# apollo510 register map
Vendor: Ambiq Micro; Series: Apollo; File version: 1.0
CPU: CM55 r1p1, little endian, MPU, FPU, double-precision FPU, DSP, I-cache, D-cache, VTOR, ITCM, DTCM, 4 interrupt priority bits, 0 interrupts, 8 SAU regions
Registers are 32-bit, read-write, reset 0x0 unless marked. A register's access mark holds for its fields unless they carry their own. Offsets are from the block's base; [hi:lo] are bit positions; {n}, {i} and the like mark numbered series; 'fields as' and 'values as' point back to an identical list.

## MCUCTRL (part 1 of 2) — MCU Miscellaneous Control Logic
Base 0x40020000
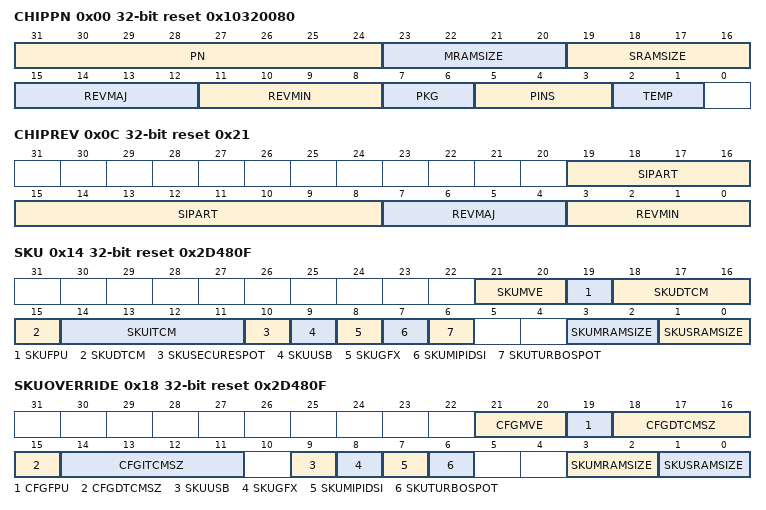
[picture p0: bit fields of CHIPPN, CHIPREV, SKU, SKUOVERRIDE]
0x00 CHIPPN reset 0x10320080 — Chip Information
  [31:24] PN — Apollo family device type.
    16=APOLLO5 (Apollo510 part number is 0x10xxxxxx.)
  [23:20] MRAMSIZE — MRAM size. Please use the SKU register for determining memory sizing.
    {v}={v+1}MB (MRAM size is {v+1}MB.) (v=0..3)
  [19:16] SRAMSIZE — SRAM size. Please use the SKU register for determining memory sizing.
    3=ITCM256K_DTCM512K_SSRAM3M (ITCM=256KB, DTCM=512KB, SSRAM=3MB); 2=ITCM256K_DTCM512K_SSRAM2M (ITCM=256KB, DTCM=512KB, SSRAM=2MB); 1=ITCM128K_DTCM256K_SSRAM2M (ITCM=128KB, DTCM=256KB, SSRAM=2MB); 0=ITCM128K_DTCM256K_SSRAM1M (ITCM=128KB, DTCM=256KB, SSRAM=1MB)
  [15:12] REVMAJ — Major revision. Please use the CHIPREV register for device identification.
  [11:8] REVMIN — Minor revision. Please use the CHIPREV register for device identification.
  [7:6] PKG — Package type.
    0=SIP (SIP package.); 1=SIP2 (SIP2 package.); 2=BGA (BGA package.); 3=CSP (CSP package.)
  [5:3] PINS — Number of pins for a given package.
    2=SIP153 (Apollo510 SIP pins = 153 (97 GPIO).); 4=BGA225 (Apollo510 BGA pins = 225 (183 GPIO).); 5=CSP182 (Apollo510 BGA pins = 182 (144 GPIO).)
  [2:1] TEMP — Temperature.
0x04 CHIPID0 — Unique Chip ID 0
  [31:0] CHIPID0 — Unique chip ID 0. For APOLLO CHIPID0 value is 0x0
0x08 CHIPID1 — Unique Chip ID 1
  [31:0] CHIPID1 — Unique chip ID 1. For APOLLO CHIPID1 value is 0x0
0x0C CHIPREV reset 0x21 — Chip Revision
  [19:8] SIPART — Silicon Part ID
  [7:4] REVMAJ — Major Revision ID.
    3=C (Apollo510 revision C); 2=B (Apollo510 revision B); 1=A (Apollo510 revision A)
  [3:0] REVMIN — Minor Revision ID.
    3=REV2 (Apollo510 minor rev 2.); 2=REV1 (Apollo510 minor rev 1.); 1=REV0 (Apollo510 minor rev 0. Minor revision value, succeeding minor revisions will increment from this value.)
0x10 VENDORID — Unique Vendor ID
  [31:0] VENDORID
    0x414D4251=AMBIQ (Ambiq Vendor ID 'AMBQ'); 0=DEFAULT (Default Vendor ID)
0x14 SKU reset 0x2D480F — Unique Chip SKU
  [21:20] SKUMVE — MVE feature 0x0: no MVE 0x1: Integer MVE only 0x2: Integer and Floating Point MVE supported (note that with this setting, FPU must be enabled)
  [19] SKUFPU — FPU feature 0x0: no FPU 0x1: Has FPU
  [18:15] SKUDTCM — DTCM size feature 0x8: 128KB 0x9: 256KB 0xA: 512KB
  [14:11] SKUITCM — ITCM size feature 0x6: 32KB 0x8: 128KB 0x9: 256KB
  [10] SKUSECURESPOT — Secure boot feature
  [9] SKUUSB — USB available
  [8] SKUGFX — GFX available
  [7] SKUMIPIDSI — MIPI DSI available
  [6] SKUTURBOSPOT — High performance mode for MCU and DSPs.
  [3:2] SKUMRAMSIZE — MRAM size SKU. All of 4MB Available by default.
    {v}={v+1}MB (Total available MRAM size is {v+1}MB.) (v=0..3)
  [1:0] SKUSRAMSIZE — SRAM SKU dictates the available memory for MCU. All of the MCU TCM (384KB) and System SRAM (2MB) available by default.
    0=1MB (Total available System SRAM size is 1MB (SSRAM0 only).); 1=2MB (Total available System SRAM size is 2MB (SSRAM0 and SSRAM1).); 3=3MB (Total available System SRAM size is 3MB (SSRAM0, SSRAM1, and SSRAM2).)
0x18 SKUOVERRIDE reset 0x2D480F — Override register for Chip SKU
  [21:20] CFGMVE — MVE feature
  [19] CFGFPU — FPU feature
  [18:15] CFGDTCMSZ — DTCM size feature (only 3 DTCM configurations are allowed: 0x8 - 128K, 0x9 - 256K, 0xA - 512K)
  [14:11] CFGITCMSZ — ITCM size feature (only 3 ITCM configurations are allowed: 0x6 - 32K, 0x8 - 128K, 0x9 - 256K)
  [9] SKUUSB — Override for usb sku
  [8] SKUGFX — Override for gfx sku
  [7] SKUMIPIDSI — Override for mipi dsi sku
  [6] SKUTURBOSPOT — Override for turbo spot sku
  [3:2] SKUMRAMSIZE — Override for mram size sku
  [1:0] SKUSRAMSIZE — Override for sram size sku
0x20 DEBUGGER — Debugger Control
  [31:0] LOCKOUT — Lockout of debugger (SWD).
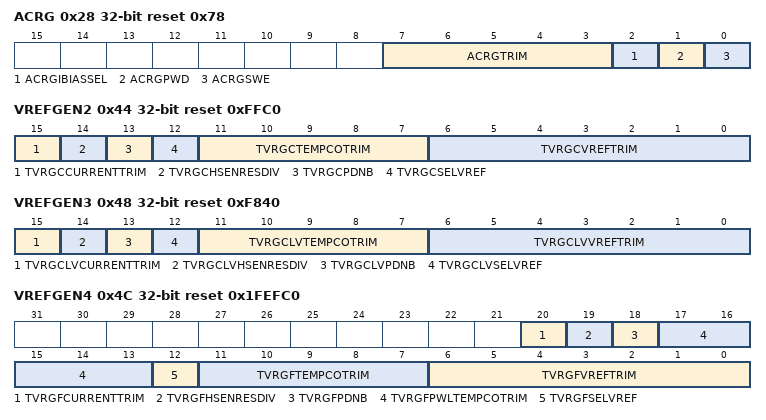
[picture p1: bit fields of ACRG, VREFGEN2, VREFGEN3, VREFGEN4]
0x28 ACRG reset 0x78 — Active Current Reference Generator Control
  [7:3] ACRGTRIM — ACRG Trim value
  [2] ACRGIBIASSEL — Set the ACRG ibias. Note: the SWE mux select in PWRSEQ2SWE must be set for this to take effect. The inversion of this register is driven to analog.
    0=BGSEL (Selects the bandgap); 1=CCRGSEL (Selects the CCRG)
  [1] ACRGPWD — Power down the ACRG.
    1=ACRG_PWR_DN (Powers down the ACRG trim.); 0=ACRG_PWR_UP (Power up the ACRG trim.)
  [0] ACRGSWE — Software enablement for ACRG register. A value of 1 will allow writes to the register
0x44 VREFGEN2 reset 0xFFC0 — Voltage Reference Generator 2 Control
  [15] TVRGCCURRENTTRIM — TVRGC Current trim init value
  [14] TVRGCHSENRESDIV — TVRGC hsenable resdiv init value
  [13] TVRGCPDNB — TVRGC pdnb init value
  [12] TVRGCSELVREF — TVRGC sel vref init value
  [11:7] TVRGCTEMPCOTRIM — TVRGC tempcompensation trim init value
  [6:0] TVRGCVREFTRIM — Calibrated Voltage Reference Generator tc trim (bottom transistor)
0x48 VREFGEN3 reset 0xF840 — Voltage Reference Generator 3 Control
  [15] TVRGCLVCURRENTTRIM — TVRGCLV Current trim init value
  [14] TVRGCLVHSENRESDIV — TVRGCLV hsenable resdiv init value
  [13] TVRGCLVPDNB — TVRGCLV pdnb init value
  [12] TVRGCLVSELVREF — TVRGCLV sel vref init value
  [11:7] TVRGCLVTEMPCOTRIM — TVRGCLV tempco trim init value
  [6:0] TVRGCLVVREFTRIM — TVRGCLV Voltage Reference Generator trim (bottom transistor)
0x4C VREFGEN4 reset 0x1FEFC0 — Voltage Reference Generator 4 Control
  [20] TVRGFCURRENTTRIM — TVRGF Current trim init value
  [19] TVRGFHSENRESDIV — TVRGF hsenable resdiv init value
  [18] TVRGFPDNB — TVRGF pdnb init value
  [17:13] TVRGFPWLTEMPCOTRIM — Calibrated Voltage Reference Generator pwl tc trim (bottom transistor)
  [12] TVRGFSELVREF — TVRGF sel vref init value
  [11:7] TVRGFTEMPCOTRIM — TVRGF tempo trim init value
  [6:0] TVRGFVREFTRIM — TVRGF Voltage Reference Generator trim (bottom transistor)
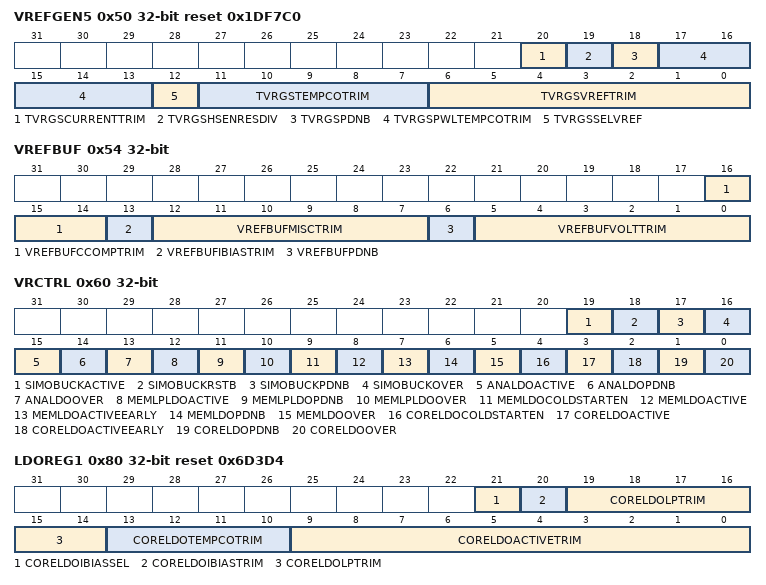
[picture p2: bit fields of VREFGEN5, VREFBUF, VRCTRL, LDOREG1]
0x50 VREFGEN5 reset 0x1DF7C0 — Voltage Reference Generator 5 Control
  [20] TVRGSCURRENTTRIM — TVRGS Current trim init value
  [19] TVRGSHSENRESDIV — TVRGS hsenable resdiv init value
  [18] TVRGSPDNB — TVRGS pdnb init value
  [17:13] TVRGSPWLTEMPCOTRIM — Calibrated Voltage Reference Generator pwl tc trim (bottom transistor)
  [12] TVRGSSELVREF — TVRGS sel vref init value
  [11:7] TVRGSTEMPCOTRIM — TVRGS tempo trim init value
  [6:0] TVRGSVREFTRIM — TVRGS Voltage Reference Generator trim (bottom transistor)
0x54 VREFBUF — Voltage Reference BUF Control
  [16:14] VREFBUFCCOMPTRIM — VREFBUF ccomp trim init value
  [13] VREFBUFIBIASTRIM — VREFBUFIBIAS trim init value
  [12:7] VREFBUFMISCTRIM — VREFBUF MISC trim init value
  [6] VREFBUFPDNB — VREGBUF pdnb init value
  [5:0] VREFBUFVOLTTRIM — VREFBUF voltage trim init value
0x60 VRCTRL — Overrides for Voltage Regulators Controls
  [19] SIMOBUCKACTIVE — SIMO BUCK ACTIVE control. Override for PWRCTRL going to analog when SIMOBUCKOVER = 1
  [18] SIMOBUCKRSTB — SIMO BUCK RSTB control. Override for PWRCTRL going to analog when SIMOBUCKOVER = 1
  [17] SIMOBUCKPDNB — SIMO BUCK PDNB control. Override for PWRCTRL going to analog when SIMOBUCKOVER = 1
  [16] SIMOBUCKOVER — Override control for SIMO BUCK signals
  [15] ANALDOACTIVE — ANALDO LDO ACTIVE control. Override for PWRCTRL going to analog when ANALDOOVER = 1
  [14] ANALDOPDNB — ANALDO PDNB control. Override for PWRCTRL going to analog when ANALDOOVER = 1
  [13] ANALDOOVER — Override control for ANALDO signals
  [12] MEMLPLDOACTIVE — MEM LP LDO ACTVIVE control. Override for PWRCTRL going to analog when MEMLPLDOOVER = 1
  [11] MEMLPLDOPDNB — MEM LP LDO PDNB control. Override for PWRCTRL going to analog when MEMLPLDOOVER = 1
  [10] MEMLPLDOOVER — Override control for MEM LP LDO signals
  [9] MEMLDOCOLDSTARTEN — MEM LDO COLDSTART EN control. This is a shadow backed register and no need to set MEMLDOOVER.
  [8] MEMLDOACTIVE — MEM LDO ACTIVE control. Override for PWRCTRL going to analog when MEMLDOOVER = 1
  [7] MEMLDOACTIVEEARLY — MEM LDO EARLY ACTIVE control. Override for PWRCTRL going to analog when MEMLDOOVER = 1
  [6] MEMLDOPDNB — MEM LDO PDNB control. Override signal for PWRCTRL going to analog when MEMLDOOVER = 1
  [5] MEMLDOOVER — Override control for MEM LDO signals
  [4] CORELDOCOLDSTARTEN — CORE LDO COLDSTART EN control. This is a shadow backed register and no need to set CORELDOOVER.
  [3] CORELDOACTIVE — CORE LDO ACTIVE control. Override for PWRCTRL going to analog when CORELDOOVER = 1
  [2] CORELDOACTIVEEARLY — CORE LDO EARLY ACTIVE control. Override for PWRCTRL going to analog when CORELDOOVER = 1
  [1] CORELDOPDNB — CORE LDO PDNB control. Override for PWRCTRL going to analog when CORELDOOVER = 1
  [0] CORELDOOVER — Override control for CORE LDO signals
0x80 LDOREG1 reset 0x6D3D4 — CORELDO trims Reg
  [21] CORELDOIBIASSEL — Core LDO IBIAS sel. Note: the SWE mux select in PWRSEQ2SWE must be set for this to take effect.
  [20] CORELDOIBIASTRIM
  [19:14] CORELDOLPTRIM — CORE LDO Low Power Trim
  [13:10] CORELDOTEMPCOTRIM
  [9:0] CORELDOACTIVETRIM
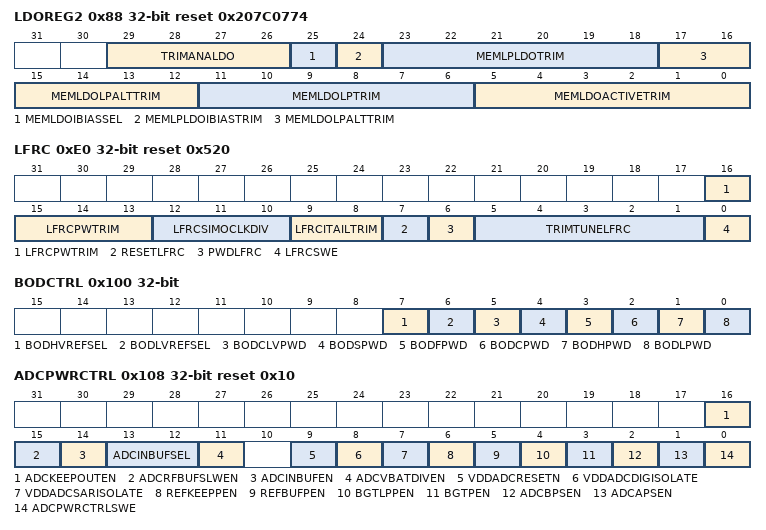
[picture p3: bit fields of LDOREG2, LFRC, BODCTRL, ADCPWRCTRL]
0x88 LDOREG2 reset 0x207C0774 — MEMLDO and MEMLPLDO Trims
  [29:26] TRIMANALDO — Analog LDO Trim.
  [25] MEMLDOIBIASSEL — Mem LDO IBIAS sel. Note: the SWE mux select in PWRSEQ2SWE must be set for this to take effect.
  [24] MEMLPLDOIBIASTRIM
  [23:18] MEMLPLDOTRIM
  [17:12] MEMLDOLPALTTRIM — MEM LDO TRIM LP ALT SET
  [11:6] MEMLDOLPTRIM
  [5:0] MEMLDOACTIVETRIM
0xE0 LFRC reset 0x520 — LFRC Control
  [16:13] LFRCPWTRIM — LFRC PW trim init value
  [12:10] LFRCSIMOCLKDIV — SIMOBUCK LP mode clock divider
    0=DIV1 (Divide by 1); 1=DIV2 (Divide by 2); 2=DIV4 (Divide by 4); 3=DIV8 (Divide by 8); 5=DIV32 (Inversion of DIV32)
  [9:8] LFRCITAILTRIM
  [7] RESETLFRC — LFRC Reset.
    0=EN (Enable LFRC.); 1=RESET (Reset LFRC.)
  [6] PWDLFRC — Power Down LFRC.
    0=PWRUP (Power up LFRC.); 1=PWRDN (Power down LFRC.)
  [5:1] TRIMTUNELFRC — LFRC Frequency Tune trim bits
  [0] LFRCSWE — LFRC Software Override Enable.
    0=OVERRIDE_DIS (LFRC Software Override Disable.); 1=OVERRIDE_EN (LFRC Software Override Enable.)
0x100 BODCTRL — BOD control
  [7] BODHVREFSEL — BODH External Reference Select. Note: the SWE mux select in PWRSEQ2SWE must be set for this to take effect.
  [6] BODLVREFSEL — BODL External Reference Select. Note: the SWE mux select in PWRSEQ2SWE must be set for this to take effect.
  [5] BODCLVPWD — BODC_LV Power Down.
  [4] BODSPWD — BODS Power Down.
  [3] BODFPWD — BODF Power Down.
  [2] BODCPWD — BODC Power Down.
  [1] BODHPWD — BODH Power Down.
  [0] BODLPWD — BODL Power Down.
0x108 ADCPWRCTRL reset 0x10 — ADC Power Control
  [16] ADCKEEPOUTEN — ADC reference keeper out en
  [15] ADCRFBUFSLWEN — ADC reference buffer slew enable
  [14] ADCINBUFEN — ADC Input Buffer Power Enable ( if the ADCPWRCTRLSWE bit is set )
  [13:12] ADCINBUFSEL — ADC input buffer mux select
  [11] ADCVBATDIVEN — ADC VBAT DIV Power Enable ( if the ADCPWRCTRLSWE bit is set )
  [9] VDDADCRESETN — RESETN signal for Power Switched SAR and Digital Controller (when global power switch is off and if the ADCPWRCTRLSWE bit is set)
    0=ASSERT (Resetn is asserted); 1=DEASSERT (Resetn is de-asserted)
  [8] VDDADCDIGISOLATE — ISOLATE signal for ADC Digital Contoller ( when ADCAPSEN is switched off and if the ADCPWRCTRLSWE bit is set)
    0=DIS (No Isolation); 1=EN (Isolate)
  [7] VDDADCSARISOLATE — ISOLATE signal for Power Switched SAR ( when ADCBPSEN is switched off )
    0=DIS (No Isolation); 1=EN (Isolate)
  [6] REFKEEPPEN — Reference Buffer Keeper Power Switch Enable
    0=DIS (Reference Buffer Keeper Power Switch disable.); 1=EN (Reference Buffer Keeper Power Switch enable.)
  [5] REFBUFPEN — Reference Buffer Power Switch Enable
    0=DIS (Reference Buffer Power Switch disable.); 1=EN (Reference Buffer Power Switch enable.)
  [4] BGTLPPEN — Bandgap and Temperature Sensor Power Switch Enable
    0=DIS (Bandgap and temperature sensor disable.); 1=EN (Bandgap and temperature sensor enable.)
  [3] BGTPEN — Bandgap and Temperature Sensor Power Switch Enable
    values as BGTLPPEN
  [2] ADCBPSEN — Enable the Analog, IO and SAR Digital logic Power Switch on when set to 1 if the ADCPWRCTRLSWE bit is set.
    0=DIS (ADC power switch software power disable.); 1=EN (ADC power switch software power enable.)
  [1] ADCAPSEN — Enable the Global ADC Power Switch on when set to 1 if the ADCPWRCTRLSWE bit is set.
    values as ADCBPSEN
  [0] ADCPWRCTRLSWE — ADC Power Control Software Override Enable
    0=OVERRIDE_DIS (ADC temperature sensor and bandgap Software Override Disable.); 1=OVERRIDE_EN (ADC temperature sensor and bandgap Software Override Enable.)
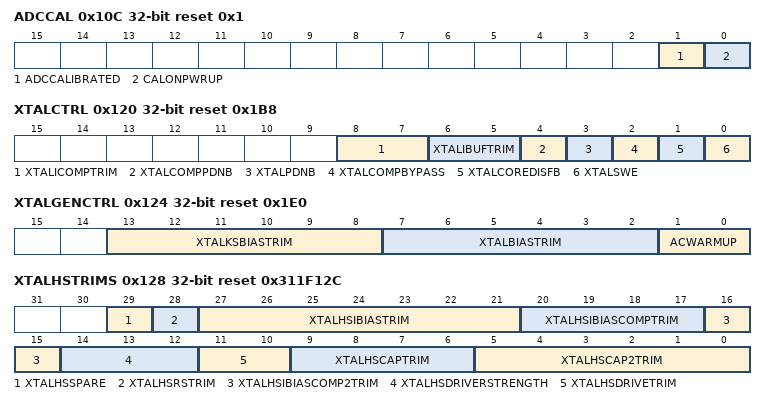
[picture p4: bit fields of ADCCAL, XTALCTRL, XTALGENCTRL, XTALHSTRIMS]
0x10C ADCCAL reset 0x1 — ADC Calibration Control
  [1] ADCCALIBRATED — Status for ADC Calibration
    0=FALSE (ADC is not calibrated); 1=TRUE (ADC is calibrated)
  [0] CALONPWRUP — Run ADC Calibration on initial power up sequence
    0=DIS (Disable automatic calibration on initial power up); 1=EN (Enable automatic calibration on initial power up)
0x110 ADCBATTLOAD — ADC Battery Load Enable
  [0] BATTLOAD — Enable the ADC battery load resistor
    0=DIS (Battery load is disconnected); 1=EN (Battery load is enabled)
0x120 XTALCTRL reset 0x1B8 — XTAL Oscillator Control
  [8:7] XTALICOMPTRIM
  [6:5] XTALIBUFTRIM — XTAL IBUFF trim
  [4] XTALCOMPPDNB — XTAL Oscillator Power Down Comparator.
    1=PWRUPCOMP (Power up XTAL oscillator comparator.); 0=PWRDNCOMP (Power down XTAL oscillator comparator.)
  [3] XTALPDNB — XTAL Oscillator Power Down Core.
    1=PWRUPCORE (Power up XTAL oscillator core.); 0=PWRDNCORE (Power down XTAL oscillator core.)
  [2] XTALCOMPBYPASS — XTAL Oscillator Bypass Comparator.
    0=USECOMP (Use the XTAL oscillator comparator.); 1=BYPCOMP (Bypass the XTAL oscillator comparator.)
  [1] XTALCOREDISFB — XTAL Oscillator Disable Feedback.
    0=EN (Enable XTAL oscillator comparator.); 1=DIS (Disable XTAL oscillator comparator.)
  [0] XTALSWE — XTAL Software Override Enable.
    0=OVERRIDE_DIS (XTAL Software Override Disable.); 1=OVERRIDE_EN (XTAL Software Override Enable.)
0x124 XTALGENCTRL reset 0x1E0 — XTAL Oscillator General Control
  [13:8] XTALKSBIASTRIM — XTAL IBIAS Kick start trim. This trim value is used during the startup process to enable a faster lock.
  [7:2] XTALBIASTRIM
  [1:0] ACWARMUP — Auto-calibration delay control
    0=SEC1 (Warmup period of 1-2 seconds); 1=SEC2 (Warmup period of 2-4 seconds); 2=SEC4 (Warmup period of 4-8 seconds); 3=SEC8 (Warmup period of 8-16 seconds)
0x128 XTALHSTRIMS reset 0x311F12C
  [29] XTALHSSPARE, [28] XTALHSRSTRIM, [27:21] XTALHSIBIASTRIM, [20:17] XTALHSIBIASCOMPTRIM, [16:15] XTALHSIBIASCOMP2TRIM, [14:12] XTALHSDRIVERSTRENGTH, [11:10] XTALHSDRIVETRIM, [9:6] XTALHSCAPTRIM, [5:0] XTALHSCAP2TRIM
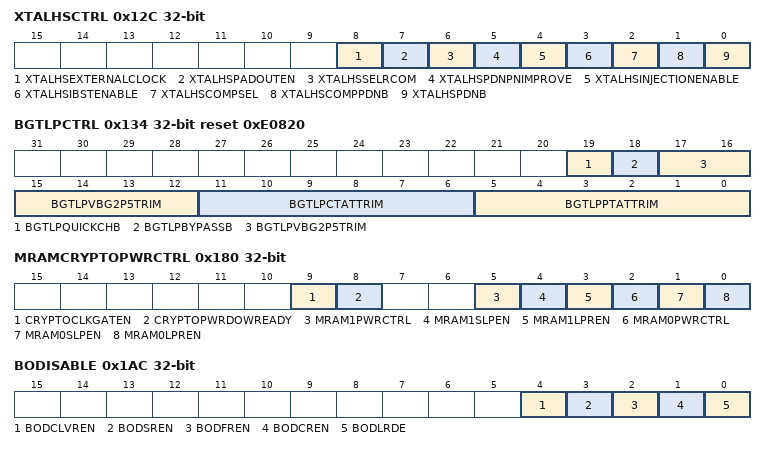
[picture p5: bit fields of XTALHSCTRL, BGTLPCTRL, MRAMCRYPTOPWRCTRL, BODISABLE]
0x12C XTALHSCTRL — XTALHS Control
  [8] XTALHSEXTERNALCLOCK, [7] XTALHSPADOUTEN, [6] XTALHSSELRCOM, [5] XTALHSPDNPNIMPROVE, [4] XTALHSINJECTIONENABLE, [3] XTALHSIBSTENABLE, [2] XTALHSCOMPSEL, [1] XTALHSCOMPPDNB, [0] XTALHSPDNB
0x134 BGTLPCTRL reset 0xE0820 — LP Bandgap Control
  [19] BGTLPQUICKCHB, [18] BGTLPBYPASSB, [17:12] BGTLPVBG2P5TRIM, [11:6] BGTLPCTATTRIM, [5:0] BGTLPPTATTRIM
0x180 MRAMCRYPTOPWRCTRL — MRAM Crypto Power Control
  [9] CRYPTOCLKGATEN — crypto clk gating enable configuration
    1=VALID (Crypto clk gating is enabled); 0=DEFAULT (Crypto clk gating is disabled at default.)
  [8] CRYPTOPWRDOWREADY — Crypto power down is ready, sw can pwd down the crypto through power ctrl
    1=VALID (Indicate Crypto is ready for power down); 0=DEFAULT (Indicate Crypto is not ready for power down.)
  [5] MRAM1PWRCTRL — MRAM1 low power mode control. When set to 1, tmc_lpr and tmc_slp are driven by the value of MRAM1LPREN and MRAM1SLPEN of this register.
  [4] MRAM1SLPEN — MRAM1 sleep mode enable
  [3] MRAM1LPREN — MRAM1 low power mode enable
  [2] MRAM0PWRCTRL — MRAM0 low power mode control. When set to 1, tmc_lpr and tmc_slp are driven by the value of MRAM0LPREN and MRAM0SLPEN of this register.
  [1] MRAM0SLPEN — MRAM0 sleep mode enable
  [0] MRAM0LPREN — MRAM0 low power mode enable
0x1AC BODISABLE — Brownout Disable
  [4] BODCLVREN — Disable VDDC_LV Brown Out reset.
    1=EN (Enable VDDC_LV Brown Out reset.); 0=DIS (Disable VDDC_LV Brown Out reset.)
  [3] BODSREN — Disable VDDS Brown Out reset.
    1=EN (Enable VDDS Brown Out reset.); 0=DIS (Disable VDDS Brown Out reset.)
  [2] BODFREN — Disable VDDF Brown Out reset.
    1=EN (Enable VDDF Brown Out reset.); 0=DIS (Disable VDDF Brown Out reset.)
  [1] BODCREN — Disable VDDC Brown Out reset.
    1=EN (Enable VDDC Brown Out reset.); 0=DIS (Disable VDDC Brown Out reset.)
  [0] BODLRDE — Disable Unregulated 1.8V Brown-out reset.
    0=EN (Enable Unregulated 1.8v brown out reset.); 1=DIS (Disable Unregulated 1.8v brown out reset.)
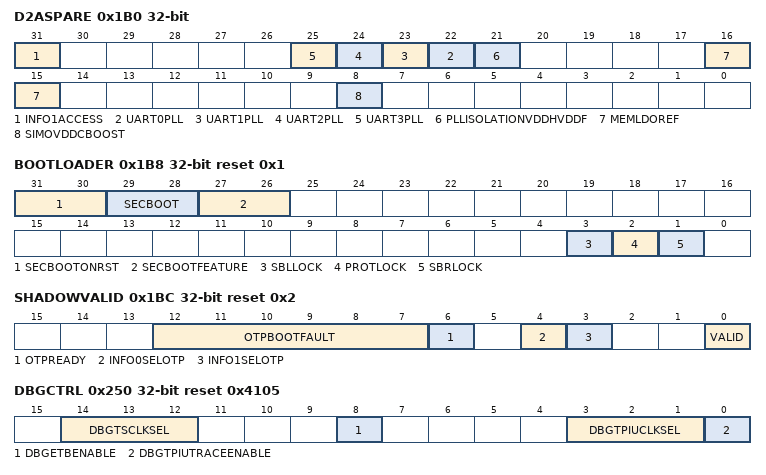
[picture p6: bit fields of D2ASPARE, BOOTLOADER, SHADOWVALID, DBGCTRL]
0x1B0 D2ASPARE — Spare registers to analog module
  [31] INFO1ACCESS — For Apollo510 revB1 or later, must be set for reliable INFO1 access.
  [n+22] UART{n}PLL (n=0..3) — UART{n} PCLK is always on. Default is 0. This bit must be set when PLL clock source is used for UART{n}.
  [21] PLLISOLATIONVDDHVDDF — PLL isolation for VDDH, VDDF.
  [16:15] MEMLDOREF — Memory LDO reference trim.
  [8] SIMOVDDCBOOST — SIMOBUCK VDDC boost.
0x1B8 BOOTLOADER reset 0x1 — Bootloader and secure boot functions
  [31:30] SECBOOTONRST — Indicates whether the secure boot on warm reset is enabled
    0=DISABLED (Secure boot disabled); 1=ENABLED (Secure boot enabled); 2=ERROR (Error in secure boot configuration)
  [29:28] SECBOOT — Indicates whether the secure boot on cold reset is enabled
    values as SECBOOTONRST
  [27:26] SECBOOTFEATURE — Indicates whether the secure boot feature is enabled.
    values as SECBOOTONRST
  [3] SBLLOCK — Secure boot loader lock. Always resets to 1, write 1 to clear. Enables system visibility to bootloader until set.
    1=LOCK (Enable the secure boot lock); 0=UNLOCK (Disable the secure boot lock)
  [2] PROTLOCK — Flash protection lock. Always resets to 1, write 1 to clear. Enables writes to flash protection register set.
    1=LOCK (Enable the secure boot lock); 0=DEFAULT (Default value.)
  [1] SBRLOCK — Secure boot ROM lock. Always resets to 1, write 1 to clear. Enables system visibility to bootloader until set.
    values as PROTLOCK
0x1BC SHADOWVALID reset 0x2 — Register to indicate whether the shadow registers have been successfully loaded from the Flash Information Space.
  [12:7] OTPBOOTFAULT — OTP interrupt status during shadow copy
    1=power_fault (Indicate OTP Power fault); 2=output_data (Conflict on OTP output data); 4=input parity check error; 8=metal shielding fault; 16=fsm_error (fsm parity error); 32=reg_error (critical reg parity error); 0=no_error (No OTP interrupt happens during boot stage)
  [6] OTPREADY — Whether OTP is ready for access
    1=VALID (Indicate OTP is ready for access); 0=DEFAULT (Default value.)
  [4] INFO0SELOTP — Select OTP Info0 or MRAM Info0.
    1=VALID (Indicate select OTP Info0); 0=DEFAULT (Default value, Select MRAM Info0)
  [3] INFO1SELOTP — Select OTP Info1 or MRAM Info1.
    1=VALID (Indicate selector OTP Info1); 0=DEFAULT (Default value, Indicate select MRAM Info1.)
  [0] VALID — Indicates whether the shadow registers contain valid data from the Flash Information Space.
    1=VALID (Flash information space contains valid data.); 0=DEFAULT (Default value.)
0x1C0 SCRATCH0 — Scratch register that is not reset by any reset
  [31:0] SCRATCH0 — Scratch register 0.
0x1C4 SCRATCH1 — Scratch register that is not reset by any reset
  [31:0] SCRATCH1 — Scratch register 1.
0x200 DBGR1 reset 0x12345678 — Read-only debug 1
  [31:0] ONETO8 — Read-only register for communication validation
0x204 DBGR2 reset 0xC001C0DE — Read-only debug 2
  [31:0] COOLCODE — Read-only register for communication validation
0x21C WICCONTROL reset 0x1 — This register is responsible for WIC Control and Configuration
  [0] DEEPISWIC — Indicates SLEEPDEEP is WIC SLEEP or Normal SLEEP
    0=SLEEPDEEP_IS_REGULAR_SLEEP (When de-asserted, SCR.SLEEPDEEP is set and the processor core is in sleep, the processor does not enter WIC sleep, and the processor must stay powered-up.); 1=SLEEPDEEP_IS_WIC_SLEEP (When asserted, SCR.SLEEPDEEP is set and the processor core is in sleep, the processor enters WIC sleep and the clock and power can both be removed from the processor.)
0x250 DBGCTRL reset 0x4105 — Debug subsystem Control. Determines the debug components enable and clk frequency.
  [14:12] DBGTSCLKSEL — This field selects the frequency of the ARM M55 dbg ts port.
    0=LOWPWR (Low power state.); 1=HFRCDIV2 (Selects HFRC divided by 2 as the source dbg ts clk); 2=HFRCDIV8 (Selects HFRC divided by 8 as the source dbg ts clk); 3=HFRCDIV16 (Selects HFRC divided by 16 as the source dbg ts clk); 4=HFRCDIV32 (Selects HFRC divided by 32 as the source dbg ts clk)
  [8] DBGETBENABLE — Debug subsystem ETB enable to store the trace data.
    0=DIS (Disable ETB.); 1=EN (Enable ETB.)
  [3:1] DBGTPIUCLKSEL — This field selects the frequency of the ARM TPIU port.
    0=OFF (Low power state.); 1=HFRC_48MHz (Selects HFRC 48Mhz as the source TPIU clk); 2=HFRC_96MHz (Selects HFRC 96Mhz as the source TPIU clk); 3=HFRC_192MHz (Selects HFRC 192Mhz as the source TPIU clk); 4=HFRC2_125MHz (Selects HFRC2 125Mhz as the source TPIU clk. Note that this setting requires CLKGEN.MISC.HFRC2 be enabled); 5=HFRC2_250MHz (Selects HFRC2 250Mhz as the source TPIU clk. Note that this setting requires CLKGEN.MISC.HFRC2 be enabled)
  [0] DBGTPIUTRACEENABLE — TPIU TRACE Enable field. When set, the Apollo510 TPIU is enabled and data can be streamed out trace data from ARM ITM and ETM modules through TRACEDATA ports
    0=DIS (Disable the TPIU TRACE.); 1=EN (Enable the TPIU TRACE.)
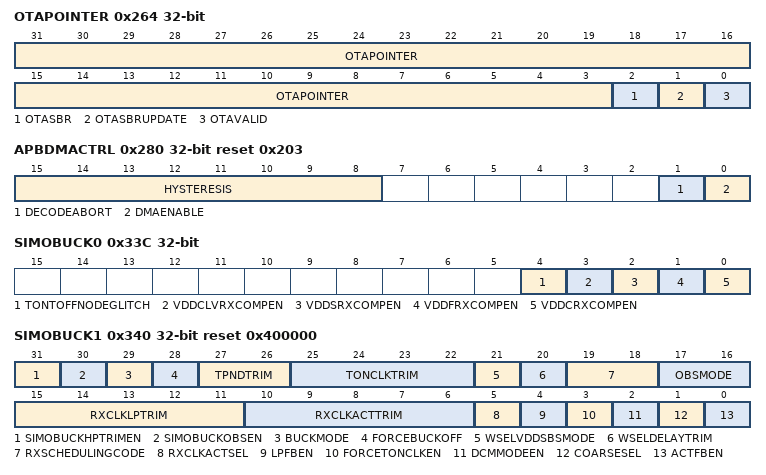
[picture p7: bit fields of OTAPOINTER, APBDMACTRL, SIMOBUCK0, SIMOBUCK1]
0x264 OTAPOINTER — OTA (Over the Air) Update Pointer/Status. Reset only by POA
  [31:3] OTAPOINTER — This register has different function depending on SBR or SBL. For SBR update, this register contains the address of the OTA image. For SBL update, this register points to the OTA Descriptor, which must be in MRAM. Since the low 3 bits have special meaning and are masked (see enums below), the pointer is required to be on an 8-byte boundary.
  [2] OTASBR — This bit (ignored in the 32-bit OTA address) indicates operation as indicated by the following enums.
    0=SBL (If OTAVALID=1, OTASBRUPDATE=0, and OTASBR=0, OTA is processed by the secure bootloader (SBL).); 1=SBR (If OTAVALID=1, OTASBRUPDATE=1, and OTASBR=1, OTA is processed by the secure bootrom (SBR).)
  [1] OTASBRUPDATE — This field must be 1 for SBR or 0 for SBL.
    0=SBL (Must be 0 for SBL update.); 1=SBR (Must be 1 for SBR update.)
  [0] OTAVALID — Indicates that an OTA update is valid
    0=INVALID (OTA update is not valid.); 1=VALID (OTA update is valid.)
0x280 APBDMACTRL reset 0x203 — DMA Control Register. Determines misc settings for DMA operation
  [15:8] HYSTERESIS — This field determines how long the DMA engine of apb/disp/gfx will remain active during deep sleep before shutting down and returning the system to full deep sleep. Values are based on a 94KHz clock and are roughly 10us increments for a range of ~10us to 2.55ms
  [1] DECODEABORT — APB Decode Abort. When set, the APB bridge will issue a data abort (bus fault) on transactions to peripherals that are powered down. When set to 0, writes are quietly discarded and reads return 0.
    0=DISABLE (Bus operations to powered down peripherals are quietly discarded); 1=ENABLE (Bus operations to powered down peripherals result in a bus fault.)
  [0] DMAENABLE — Enable the DMA controller. When disabled, DMA requests will be ignored by the controller
    0=DISABLE (DMA operations disabled); 1=ENABLE (DMA operations enabled)
0x284 FORCEAXICLKEN — Force AXI Clock Enabled
  [0] FRCAXICLKEN — This bit will override the AXI fabric clock enable logic to force it on.
0x338 KEXTCLKSEL — Locks the state of the EXTCLKSEL register from writes. This is done to prevent errant writes to the register, as this could cause the chip to halt. Write a value of 0x53 to unlock write access to the EXTCLKSEL register. Once unlocked, the register will read back a 1 to undicate this is unlocked. Writing the register with any other value other than 0x53 will enable the lock.
  [31:0] KEXTCLKSEL — Key register value.
    83=Key (Key value to unlock the register.)
0x33C SIMOBUCK0 — This WRITE_ONLY register controls various buck parameters. It will read back as 0x00000000.
  [4] TONTOFFNODEGLITCH — Enable the ton and toff signals no deglitch output.
  [3] VDDCLVRXCOMPEN — Enable the VDDC LV rail.
  [2] VDDSRXCOMPEN — Enable the VDDS rail.
  [1] VDDFRXCOMPEN — Enable the VDDS rail.
  [0] VDDCRXCOMPEN — Enable the VDDC rail.
0x340 SIMOBUCK1 reset 0x400000 — 1. Control the even division of 3 clocks: refresh, low power and TONCLK. 2. Control gap bewteen secondary switches. 3. Debug features: control the amount of time TONCLK is on, and the time before snubber asserts for each buck sequence. 4. Enable or disable the observation bus. 5. Select the buck sequence operation mode. 6. Control delay between primary Pmos and Nmos transitions.
  [31] SIMOBUCKHPTRIMEN — Enable the simobuck HP mode trim
    0=SIMOBUCK_HP_OFF (Disable simobuck hp trim.); 1=SIMOBUCK_HP_ON (Enable simobuck hp trim.)
  [30] SIMOBUCKOBSEN — Enable the simobuck observation bus output.
    0=SIMO_DATA_OFF (Disable simobuck data output.); 1=SIMO_DATA_ON (Enable simobuck data output.)
  [29] BUCKMODE — The buck sequence can operate in two buck sequence modes: default (zxcomp) and backup. Set before simobuck comes up.
    0=ZXCOMP (Select default (ZXCOMP) sequence operating mode.); 1=NOZXCOMP (Select backup sequence operating mode.)
  [28] FORCEBUCKOFF — Control the buck sequence stopping point before snubber asserts. Set before simobuck comes up.
    0=VARIED_CYCLES (Stop point will vary depending on operating mode.); 1=TWO_CYCLE (Stop exactly 1 TONCLK cycle before snubber asserts.)
  [27:26] TPNDTRIM — Control delay between primary Pmos and Nmos transitions.
  [25:22] TONCLKTRIM — This divides the 100 MHz ton clock. Even divides are supported only. This value represents the division amount minus 1.
  [21] WSELVDDSBSMODE — DEPRECATED
  [20] WSELDELAYTRIM — DEPRECATED
  [19:18] RXSCHEDULINGCODE — DEPRECATED
  [17:16] OBSMODE — Choose from 4 modes of operation
  [15:11] RXCLKLPTRIM — This divides the 32 kHz low power clock. Even divides are supported only. This value represents the division amount minus 1.
  [10:6] RXCLKACTTRIM — This divides the 5 MHz refresh clock. Even divides are supported only. This value represents the division amount minus 1.
  [5] RXCLKACTSEL — DEPRECATED
  [4] LPFBEN — DEPRECATED
  [3] FORCETONCLKEN — TONCLK is active only when needed to save power. This keeps the clock always on (AON). Set before simobuck comes up.
    0=LP_TONCLK (TONCLK will be active only when needed.); 1=AON_TONCLK (TONCLK is always on.)
  [2] DCMMODEEN — DEPRECATED
  [1] COARSESEL — DEPRECATED
  [0] ACTFBEN — DEPRECATED
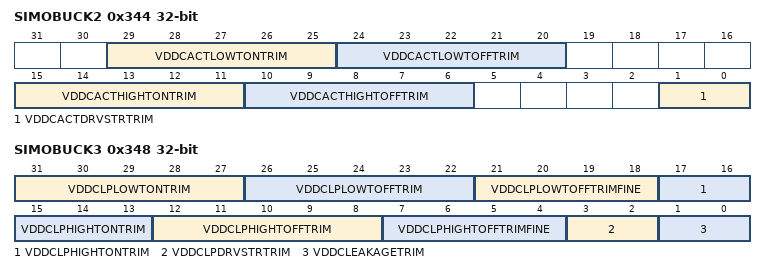
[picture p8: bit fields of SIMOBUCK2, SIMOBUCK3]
0x344 SIMOBUCK2 — SIMO Buck Muxed VDDC Active Sequence Trim Control
  [29:25] VDDCACTLOWTONTRIM — VDDC active high ton trim control for Buck sequence.
  [24:20] VDDCACTLOWTOFFTRIM — VDDC active low toff trim control for Buck sequence.
  [15:11] VDDCACTHIGHTONTRIM — VDDC active high ton trim control for Buck sequence.
  [10:6] VDDCACTHIGHTOFFTRIM — VDDC active high toff trim control for Buck sequence.
  [1:0] VDDCACTDRVSTRTRIM — VDDC active trim control for drive strength.
0x348 SIMOBUCK3 — SIMO Buck Muxed VDDC low power Sequence Trim Control
  [31:27] VDDCLPLOWTONTRIM — VDDC LP low ton trim control for Buck sequence.
  [26:22] VDDCLPLOWTOFFTRIM — VDDC LP low toff trim control for Buck sequence.
  [21:18] VDDCLPLOWTOFFTRIMFINE — DEPRECATED.
  [17:13] VDDCLPHIGHTONTRIM — VDDC LP high ton trim control for Buck sequence.
  [12:8] VDDCLPHIGHTOFFTRIM — VDDC LP high toff trim control for Buck sequence.
  [7:4] VDDCLPHIGHTOFFTRIMFINE — DEPRECATED.
  [3:2] VDDCLPDRVSTRTRIM — VDDC LP trim control for drive strength.
  [1:0] VDDCLEAKAGETRIM — DEPRECATED
